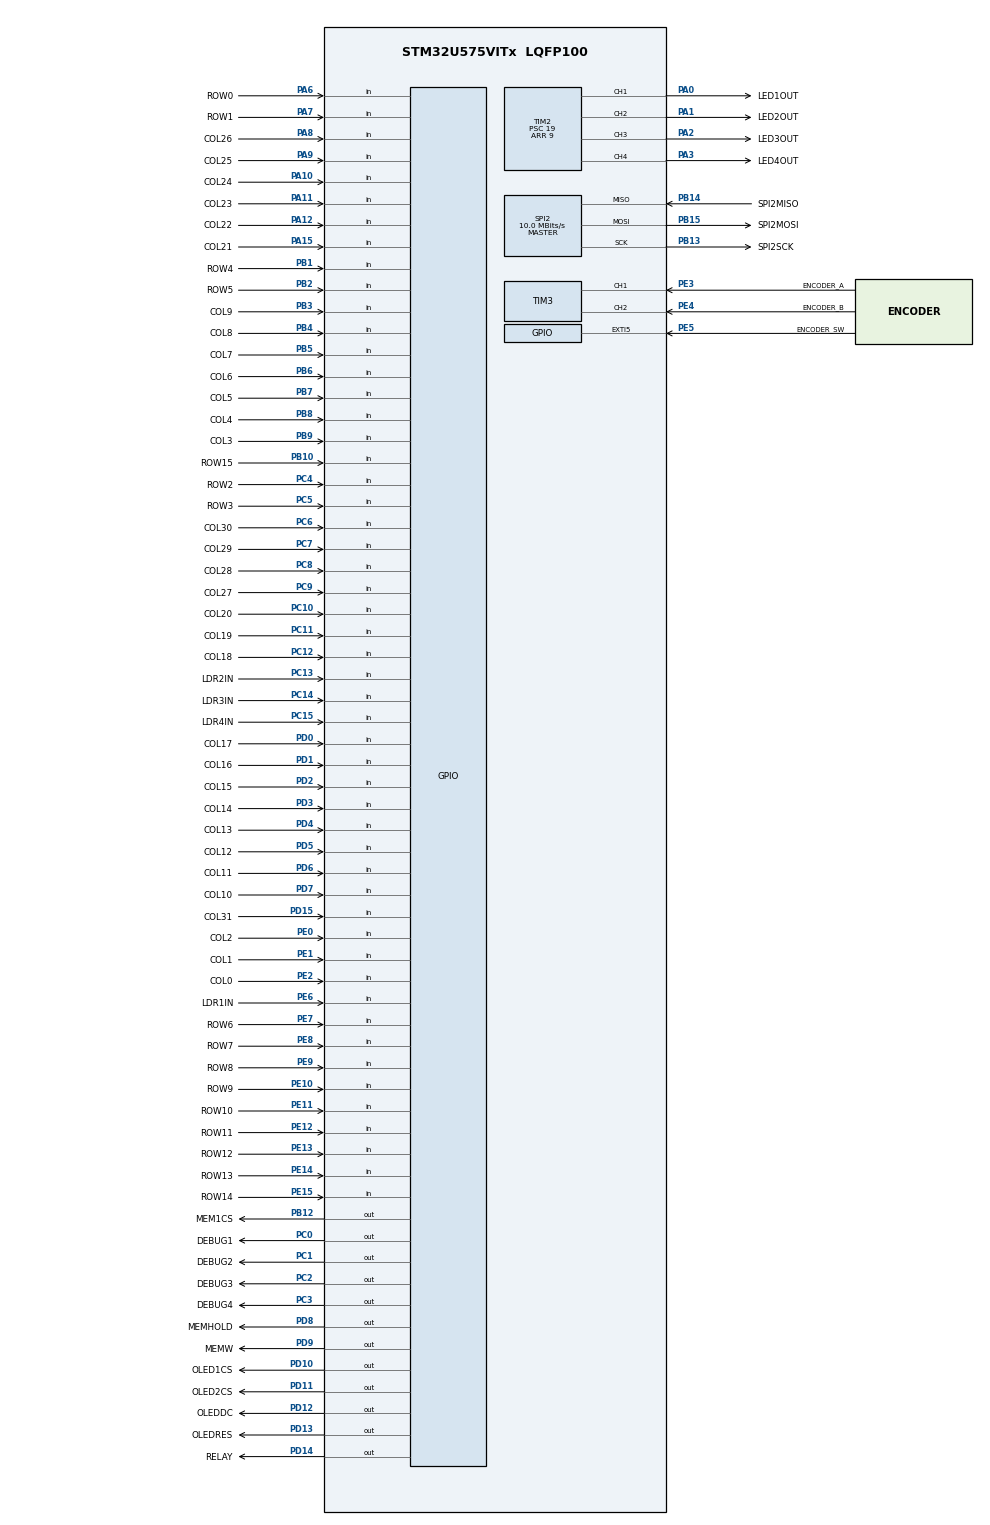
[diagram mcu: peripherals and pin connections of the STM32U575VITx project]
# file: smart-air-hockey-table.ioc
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CORTEX_M33_NS.userName=CORTEX_M33
GPDMA1.DATAHANDLING_GPDMACH0=ENABLE
GPDMA1.DATAHANDLING_GPDMACH1=ENABLE
GPDMA1.DATAHANDLING_GPDMACH2=ENABLE
GPDMA1.DATAHANDLING_GPDMACH3=ENABLE
GPDMA1.DESTDATAWIDTH_GPDMACH0=DMA_DEST_DATAWIDTH_WORD
GPDMA1.DESTDATAWIDTH_GPDMACH1=DMA_DEST_DATAWIDTH_WORD
GPDMA1.DESTDATAWIDTH_GPDMACH2=DMA_DEST_DATAWIDTH_WORD
GPDMA1.DESTDATAWIDTH_GPDMACH3=DMA_DEST_DATAWIDTH_WORD
GPDMA1.DIRECTION_GPDMACH0=DMA_MEMORY_TO_PERIPH
GPDMA1.DIRECTION_GPDMACH1=DMA_MEMORY_TO_PERIPH
GPDMA1.DIRECTION_GPDMACH2=DMA_MEMORY_TO_PERIPH
GPDMA1.DIRECTION_GPDMACH3=DMA_MEMORY_TO_PERIPH
GPDMA1.IPHANDLE_GPDMACH0-SIMPLEREQUEST_GPDMACH0=__NULL
GPDMA1.IPHANDLE_GPDMACH1-SIMPLEREQUEST_GPDMACH1=__NULL
GPDMA1.IPHANDLE_GPDMACH2-SIMPLEREQUEST_GPDMACH2=__NULL
GPDMA1.IPHANDLE_GPDMACH3-SIMPLEREQUEST_GPDMACH3=__NULL
GPDMA1.REQUEST_GPDMACH0=GPDMA1_REQUEST_TIM2_UP
GPDMA1.REQUEST_GPDMACH1=GPDMA1_REQUEST_TIM2_UP
GPDMA1.REQUEST_GPDMACH2=GPDMA1_REQUEST_TIM2_UP
GPDMA1.REQUEST_GPDMACH3=GPDMA1_REQUEST_TIM2_UP
GPDMA1.SRCINC_GPDMACH0=DMA_SINC_INCREMENTED
GPDMA1.SRCINC_GPDMACH1=DMA_SINC_INCREMENTED
GPDMA1.SRCINC_GPDMACH2=DMA_SINC_INCREMENTED
GPDMA1.SRCINC_GPDMACH3=DMA_SINC_INCREMENTED
GPDMA1.TRANSFERALLOCATEDPORTSRC_GPDMACH0=DMA_SRC_ALLOCATED_PORT1
GPDMA1.TRANSFERALLOCATEDPORTSRC_GPDMACH1=DMA_SRC_ALLOCATED_PORT1
GPDMA1.TRANSFERALLOCATEDPORTSRC_GPDMACH2=DMA_SRC_ALLOCATED_PORT1
GPDMA1.TRANSFERALLOCATEDPORTSRC_GPDMACH3=DMA_SRC_ALLOCATED_PORT1
Mcu.Family=STM32U5
Mcu.Name=STM32U575VITx
Mcu.Package=LQFP100
NVIC.EXTI5_IRQn=true\:3\:0\:true\:false\:true\:true\:true\:true
NVIC.GPDMA1_Channel0_IRQn=true\:3\:0\:true\:false\:true\:false\:true\:true
NVIC.GPDMA1_Channel1_IRQn=true\:3\:0\:true\:false\:true\:false\:true\:true
NVIC.GPDMA1_Channel2_IRQn=true\:3\:0\:true\:false\:true\:false\:true\:true
NVIC.GPDMA1_Channel3_IRQn=true\:3\:0\:true\:false\:true\:false\:true\:true
NVIC.PriorityGroup=NVIC_PRIORITYGROUP_4
NVIC.TIM6_IRQn=true\:1\:0\:true\:false\:true\:true\:true\:true
NVIC.TIM7_IRQn=true\:2\:0\:true\:false\:true\:true\:true\:true
PA0.GPIO_Label=LED1OUT
PA0.Signal=S_TIM2_CH1
PA1.GPIO_Label=LED2OUT
PA1.Signal=S_TIM2_CH2
PA10.GPIO_Label=COL24
PA10.Signal=GPIO_Input
PA11.GPIO_Label=COL23
PA11.Signal=GPIO_Input
PA12.GPIO_Label=COL22
PA12.Signal=GPIO_Input
PA13\ (JTMS/SWDIO).GPIO_Label=SWDIO
PA13\ (JTMS/SWDIO).Mode=Serial_Wire
PA13\ (JTMS/SWDIO).Signal=DEBUG_JTMS-SWDIO
PA14\ (JTCK/SWCLK).GPIO_Label=SWCLK
PA14\ (JTCK/SWCLK).Mode=Serial_Wire
PA14\ (JTCK/SWCLK).Signal=DEBUG_JTCK-SWCLK
PA15\ (JTDI).GPIO_Label=COL21
PA15\ (JTDI).Signal=GPIO_Input
PA2.GPIO_Label=LED3OUT
PA2.Signal=S_TIM2_CH3
PA3.GPIO_Label=LED4OUT
PA3.Signal=S_TIM2_CH4
PA6.GPIO_Label=ROW0
PA6.Signal=GPIO_Input
PA7.GPIO_Label=ROW1
PA7.Signal=GPIO_Input
PA8.GPIO_Label=COL26
PA8.Signal=GPIO_Input
PA9.GPIO_Label=COL25
PA9.Signal=GPIO_Input
PB1.GPIO_Label=ROW4
PB1.Signal=GPIO_Input
PB10.GPIO_Label=ROW15
PB10.Signal=GPIO_Input
PB12.GPIO_Label=MEM1CS
PB12.Signal=GPIO_Output
PB13.GPIO_Label=SPI2SCK
PB13.Mode=Full_Duplex_Master
PB13.Signal=SPI2_SCK
PB14.GPIO_Label=SPI2MISO
PB14.Mode=Full_Duplex_Master
PB14.Signal=SPI2_MISO
PB15.GPIO_Label=SPI2MOSI
PB15.Mode=Full_Duplex_Master
PB15.Signal=SPI2_MOSI
PB2.GPIO_Label=ROW5
PB2.Signal=GPIO_Input
PB3\ (JTDO/TRACESWO).GPIO_Label=COL9
PB3\ (JTDO/TRACESWO).Signal=GPIO_Input
PB4\ (NJTRST).GPIO_Label=COL8
PB4\ (NJTRST).Signal=GPIO_Input
PB5.GPIO_Label=COL7
PB5.Signal=GPIO_Input
PB6.GPIO_Label=COL6
PB6.Signal=GPIO_Input
PB7.GPIO_Label=COL5
PB7.Signal=GPIO_Input
PB8.GPIO_Label=COL4
PB8.Signal=GPIO_Input
PB9.GPIO_Label=COL3
PB9.Signal=GPIO_Input
PC0.GPIO_Label=DEBUG1
PC0.Signal=GPIO_Output
PC1.GPIO_Label=DEBUG2
PC1.Signal=GPIO_Output
PC10.GPIO_Label=COL20
PC10.Signal=GPIO_Input
PC11.GPIO_Label=COL19
PC11.Signal=GPIO_Input
PC12.GPIO_Label=COL18
PC12.Signal=GPIO_Input
PC13.GPIO_Label=LDR2IN
PC13.GPIO_PuPd=GPIO_PULLUP
PC13.Signal=GPIO_Input
PC14-OSC32_IN\ (PC14).GPIO_Label=LDR3IN
PC14-OSC32_IN\ (PC14).GPIO_PuPd=GPIO_PULLUP
PC14-OSC32_IN\ (PC14).Signal=GPIO_Input
PC15-OSC32_OUT\ (PC15).GPIO_Label=LDR4IN
PC15-OSC32_OUT\ (PC15).GPIO_PuPd=GPIO_PULLUP
PC15-OSC32_OUT\ (PC15).Signal=GPIO_Input
PC2.GPIO_Label=DEBUG3
PC2.Signal=GPIO_Output
PC3.GPIO_Label=DEBUG4
PC3.Signal=GPIO_Output
PC4.GPIO_Label=ROW2
PC4.Signal=GPIO_Input
PC5.GPIO_Label=ROW3
PC5.Signal=GPIO_Input
PC6.GPIO_Label=COL30
PC6.Signal=GPIO_Input
PC7.GPIO_Label=COL29
PC7.Signal=GPIO_Input
PC8.GPIO_Label=COL28
PC8.Signal=GPIO_Input
PC9.GPIO_Label=COL27
PC9.Signal=GPIO_Input
PD0.GPIO_Label=COL17
PD0.Signal=GPIO_Input
PD1.GPIO_Label=COL16
PD1.Signal=GPIO_Input
PD10.GPIO_Label=OLED1CS
PD10.Signal=GPIO_Output
PD11.GPIO_Label=OLED2CS
PD11.Signal=GPIO_Output
PD12.GPIO_Label=OLEDDC
PD12.Signal=GPIO_Output
PD13.GPIO_Label=OLEDRES
PD13.Signal=GPIO_Output
PD14.GPIO_Label=RELAY
PD14.Signal=GPIO_Output
PD15.GPIO_Label=COL31
PD15.Signal=GPIO_Input
PD2.GPIO_Label=COL15
PD2.Signal=GPIO_Input
PD3.GPIO_Label=COL14
PD3.Signal=GPIO_Input
PD4.GPIO_Label=COL13
PD4.Signal=GPIO_Input
PD5.GPIO_Label=COL12
PD5.Signal=GPIO_Input
PD6.GPIO_Label=COL11
PD6.Signal=GPIO_Input
PD7.GPIO_Label=COL10
PD7.Signal=GPIO_Input
PD8.GPIO_Label=MEMHOLD
PD8.Signal=GPIO_Output
PD9.GPIO_Label=MEMW
PD9.Signal=GPIO_Output
PE0.GPIO_Label=COL2
PE0.Signal=GPIO_Input
PE1.GPIO_Label=COL1
PE1.Signal=GPIO_Input
PE10.GPIO_Label=ROW9
PE10.Signal=GPIO_Input
PE11.GPIO_Label=ROW10
PE11.Signal=GPIO_Input
PE12.GPIO_Label=ROW11
PE12.Signal=GPIO_Input
PE13.GPIO_Label=ROW12
PE13.Signal=GPIO_Input
PE14.GPIO_Label=ROW13
PE14.Signal=GPIO_Input
PE15.GPIO_Label=ROW14
PE15.Signal=GPIO_Input
PE2.GPIO_Label=COL0
PE2.Signal=GPIO_Input
PE3.GPIO_Label=ENCODER_A
PE3.GPIO_PuPd=GPIO_PULLUP
PE3.Signal=S_TIM3_CH1
PE4.GPIO_Label=ENCODER_B
PE4.GPIO_PuPd=GPIO_PULLUP
PE4.Signal=S_TIM3_CH2
PE5.GPIO_Label=ENCODER_SW
PE5.GPIO_ModeDefaultEXTI=GPIO_MODE_IT_FALLING
PE5.GPIO_PuPd=GPIO_PULLUP
PE5.Signal=GPXTI5
PE6.GPIO_Label=LDR1IN
PE6.GPIO_PuPd=GPIO_PULLUP
PE6.Signal=GPIO_Input
PE7.GPIO_Label=ROW6
PE7.Signal=GPIO_Input
PE8.GPIO_Label=ROW7
PE8.Signal=GPIO_Input
PE9.GPIO_Label=ROW8
PE9.Signal=GPIO_Input
PH0-OSC_IN\ (PH0).GPIO_Label=OSC_IN
PH0-OSC_IN\ (PH0).Mode=HSE-External-Clock-Source
PH0-OSC_IN\ (PH0).Signal=RCC_OSC_IN
ProjectManager.HeapSize=0x200
ProjectManager.StackSize=0x400
ProjectManager.TargetToolchain=STM32CubeIDE
RCC.ADCFreq_Value=16000000
RCC.AHBFreq_Value=160000000
RCC.APB1Freq_Value=160000000
RCC.APB1TimFreq_Value=160000000
RCC.APB2Freq_Value=160000000
RCC.APB2TimFreq_Value=160000000
RCC.APB3Freq_Value=160000000
RCC.CortexFreq_Value=160000000
RCC.EPOD_VALUE=4000000
RCC.HCLKFreq_Value=160000000
RCC.HSE_VALUE=16000000
RCC.HSI48_VALUE=48000000
RCC.HSI_VALUE=16000000
RCC.LSE_VALUE=32768
RCC.LSIDIV_VALUE=32000
RCC.MSI_VALUE=4000000
RCC.PLLN=80
RCC.SYSCLKFreq_VALUE=160000000
RCC.SYSCLKSource=RCC_SYSCLKSOURCE_PLLCLK
RCC.USBFreq_Value=48000000
RCC.VCOOutputFreq_Value=320000000
SH.S_TIM2_CH1.0=TIM2_CH1,PWM Generation1 CH1
SH.S_TIM2_CH2.0=TIM2_CH2,PWM Generation2 CH2
SH.S_TIM2_CH3.0=TIM2_CH3,PWM Generation3 CH3
SH.S_TIM2_CH4.0=TIM2_CH4,PWM Generation4 CH4
SH.S_TIM3_CH1.0=TIM3_CH1,Encoder_Interface
SH.S_TIM3_CH2.0=TIM3_CH2,Encoder_Interface
SPI2.BaudRatePrescaler=SPI_BAUDRATEPRESCALER_16
SPI2.CalculateBaudRate=10.0 MBits/s
SPI2.DataSize=SPI_DATASIZE_8BIT
SPI2.Direction=SPI_DIRECTION_2LINES
SPI2.Mode=SPI_MODE_MASTER
SPI2.VirtualType=VM_MASTER
TIM2.Channel-PWM\ Generation1\ CH1=TIM_CHANNEL_1
TIM2.Channel-PWM\ Generation2\ CH2=TIM_CHANNEL_2
TIM2.Channel-PWM\ Generation3\ CH3=TIM_CHANNEL_3
TIM2.Channel-PWM\ Generation4\ CH4=TIM_CHANNEL_4
TIM2.PeriodNoDither=9
TIM2.Prescaler=19
TIM3.EncoderMode=TIM_ENCODERMODE_TI12
TIM3.IC1Filter=8
TIM3.IC2Filter=8
TIM6.PeriodNoDither=9
TIM6.Prescaler=15999
TIM7.PeriodNoDither=9
TIM7.Prescaler=15999
VP_GPDMA1_VS_GPDMACH0.Mode=SIMPLEREQUEST_GPDMACH0
VP_GPDMA1_VS_GPDMACH1.Mode=SIMPLEREQUEST_GPDMACH1
VP_GPDMA1_VS_GPDMACH2.Mode=SIMPLEREQUEST_GPDMACH2
VP_GPDMA1_VS_GPDMACH3.Mode=SIMPLEREQUEST_GPDMACH3
VP_ICACHE_VS_ICACHE.Mode=DirectMappedCache
VP_LPBAMQUEUE_VS_QUEUE.Mode=QUEUEMODE
VP_LPBAM_VS_SIG1.Mode=SmartRun
VP_LPBAM_VS_SIG4.Mode=LPDMA1
VP_MEMORYMAP_VS_MEMORYMAP.Mode=CurAppReg
VP_PWR_VS_SECSignals.Mode=Security/Privilege
VP_TIM2_VS_ClockSourceINT.Mode=Internal
VP_TIM6_VS_ClockSourceINT.Mode=Enable_Timer
VP_TIM7_VS_ClockSourceINT.Mode=Enable_Timer
board=custom

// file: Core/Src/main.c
/* USER CODE BEGIN Header */
/**
  ******************************************************************************
  * @file           : main.c
  * @brief          : Main program body
  ******************************************************************************
  * @attention
  *
  * Copyright (c) 2023 STMicroelectronics.
  * All rights reserved.
  *
  * This software is licensed under terms that can be found in the LICENSE file
  * in the root directory of this software component.
  * If no LICENSE file comes with this software, it is provided AS-IS.
  *
  ******************************************************************************
  */
/* USER CODE END Header */
#include "main.h"

/* USER CODE BEGIN Includes */
#include "app_core.h"
/* USER CODE END Includes */

void SystemClock_Config(void);
static void MX_GPDMA1_Init(void);
static void MX_GPIO_Init(void);
static void MX_MEMORYMAP_Init(void);
static void MX_ICACHE_Init(void);
static void MX_SPI2_Init(void);
static void MX_TIM2_Init(void);
static void MX_TIM3_Init(void);
static void MX_TIM6_Init(void);
static void MX_TIM7_Init(void);

int main(void)
{

  /* MCU Configuration--------------------------------------------------------*/

  /* Reset of all peripherals, Initializes the Flash interface and the Systick. */
  HAL_Init();

  /* Enable PWR clock interface */

  LL_AHB3_GRP1_EnableClock(LL_AHB3_GRP1_PERIPH_PWR);

  /* Configure the system clock */
  SystemClock_Config();

  /* Initialize all configured peripherals */
  MX_GPDMA1_Init();
  MX_GPIO_Init();
  MX_MEMORYMAP_Init();
  MX_ICACHE_Init();
  MX_SPI2_Init();
  MX_TIM2_Init();
  MX_TIM3_Init();
  MX_TIM6_Init();
  MX_TIM7_Init();
  /* USER CODE BEGIN 2 */
  App_Init();
  /* USER CODE END 2 */

  /* Infinite loop */
  while (1)
  {

    /* USER CODE BEGIN 3 */
    asm("wfi");
  }
  /* USER CODE END 3 */
}

void SystemClock_Config(void)
{
  LL_FLASH_SetLatency(LL_FLASH_LATENCY_4);
  while(LL_FLASH_GetLatency()!= LL_FLASH_LATENCY_4)
  {
  }

  LL_PWR_SetRegulVoltageScaling(LL_PWR_REGU_VOLTAGE_SCALE1);
  while (LL_PWR_IsActiveFlag_VOS() == 0)
  {
  }
  LL_RCC_MSIS_Enable();

   /* Wait till MSIS is ready */
  while(LL_RCC_MSIS_IsReady() != 1)
  {
  }

  LL_RCC_MSI_EnableRangeSelection();
  LL_RCC_MSIS_SetRange(LL_RCC_MSISRANGE_4);
  LL_RCC_MSI_SetCalibTrimming(16, LL_RCC_MSI_OSCILLATOR_1);
  LL_RCC_PLL1_ConfigDomain_SYS(LL_RCC_PLL1SOURCE_MSIS, 1, 80, 2);
  LL_RCC_PLL1_EnableDomain_SYS();
  LL_RCC_SetPll1EPodPrescaler(LL_RCC_PLL1MBOOST_DIV_1);
  LL_RCC_PLL1_SetVCOInputRange(LL_RCC_PLLINPUTRANGE_4_8);
  LL_RCC_PLL1_Enable();

   /* Wait till PLL is ready */
  while(LL_RCC_PLL1_IsReady() != 1)
  {
  }

   /* Intermediate AHB prescaler 2 when target frequency clock is higher than 80 MHz */
  LL_RCC_SetAHBPrescaler(LL_RCC_SYSCLK_DIV_2);

  LL_RCC_SetSysClkSource(LL_RCC_SYS_CLKSOURCE_PLL1);

   /* Wait till System clock is ready */
  while(LL_RCC_GetSysClkSource() != LL_RCC_SYS_CLKSOURCE_STATUS_PLL1)
  {
  }

  /* Insure 1us transition state at intermediate medium speed clock*/
  for (__IO uint32_t i = (160 >> 1); i !=0; i--);

  LL_RCC_SetAHBPrescaler(LL_RCC_SYSCLK_DIV_1);
  LL_RCC_SetAPB1Prescaler(LL_RCC_APB1_DIV_1);
  LL_RCC_SetAPB2Prescaler(LL_RCC_APB2_DIV_1);
  LL_RCC_SetAPB3Prescaler(LL_RCC_APB3_DIV_1);
  LL_SetSystemCoreClock(160000000);

   /* Update the time base */
  if (HAL_InitTick (TICK_INT_PRIORITY) != HAL_OK)
  {
    Error_Handler();
  }
}

static void MX_GPDMA1_Init(void)
{

  /* Peripheral clock enable */
  LL_AHB1_GRP1_EnableClock(LL_AHB1_GRP1_PERIPH_GPDMA1);

  /* GPDMA1 interrupt Init */
  NVIC_SetPriority(GPDMA1_Channel0_IRQn, NVIC_EncodePriority(NVIC_GetPriorityGrouping(),3, 0));
  NVIC_EnableIRQ(GPDMA1_Channel0_IRQn);
  NVIC_SetPriority(GPDMA1_Channel1_IRQn, NVIC_EncodePriority(NVIC_GetPriorityGrouping(),3, 0));
  NVIC_EnableIRQ(GPDMA1_Channel1_IRQn);
  NVIC_SetPriority(GPDMA1_Channel2_IRQn, NVIC_EncodePriority(NVIC_GetPriorityGrouping(),3, 0));
  NVIC_EnableIRQ(GPDMA1_Channel2_IRQn);
  NVIC_SetPriority(GPDMA1_Channel3_IRQn, NVIC_EncodePriority(NVIC_GetPriorityGrouping(),3, 0));
  NVIC_EnableIRQ(GPDMA1_Channel3_IRQn);

}

static void MX_ICACHE_Init(void)
{

  /** Enable instruction cache in 1-way (direct mapped cache)
  */
  LL_ICACHE_SetMode(LL_ICACHE_1WAY);
  LL_ICACHE_Enable();

}

static void MX_MEMORYMAP_Init(void)
{

}

static void MX_SPI2_Init(void)
{

  LL_SPI_InitTypeDef SPI_InitStruct = {0};

  LL_GPIO_InitTypeDef GPIO_InitStruct = {0};

  LL_RCC_SetSPIClockSource(LL_RCC_SPI2_CLKSOURCE_SYSCLK);

  /* Peripheral clock enable */
  LL_APB1_GRP1_EnableClock(LL_APB1_GRP1_PERIPH_SPI2);

  LL_AHB2_GRP1_EnableClock(LL_AHB2_GRP1_PERIPH_GPIOB);
  /**SPI2 GPIO Configuration
  PB13   ------> SPI2_SCK
  PB14   ------> SPI2_MISO
  PB15   ------> SPI2_MOSI
  */
  GPIO_InitStruct.Pin = SPI2SCK_Pin|SPI2MISO_Pin|SPI2MOSI_Pin;
  GPIO_InitStruct.Mode = LL_GPIO_MODE_ALTERNATE;
  GPIO_InitStruct.Speed = LL_GPIO_SPEED_FREQ_LOW;
  GPIO_InitStruct.OutputType = LL_GPIO_OUTPUT_PUSHPULL;
  GPIO_InitStruct.Pull = LL_GPIO_PULL_NO;
  GPIO_InitStruct.Alternate = LL_GPIO_AF_5;
  LL_GPIO_Init(GPIOB, &GPIO_InitStruct);

  /* SPI2 parameter configuration*/
  SPI_InitStruct.TransferDirection = LL_SPI_FULL_DUPLEX;
  SPI_InitStruct.Mode = LL_SPI_MODE_MASTER;
  SPI_InitStruct.DataWidth = LL_SPI_DATAWIDTH_8BIT;
  SPI_InitStruct.ClockPolarity = LL_SPI_POLARITY_LOW;
  SPI_InitStruct.ClockPhase = LL_SPI_PHASE_1EDGE;
  SPI_InitStruct.NSS = LL_SPI_NSS_SOFT;
  SPI_InitStruct.BaudRate = LL_SPI_BAUDRATEPRESCALER_DIV16;
  SPI_InitStruct.BitOrder = LL_SPI_MSB_FIRST;
  SPI_InitStruct.CRCCalculation = LL_SPI_CRCCALCULATION_DISABLE;
  SPI_InitStruct.CRCPoly = 0x7;
  LL_SPI_Init(SPI2, &SPI_InitStruct);
  LL_SPI_SetStandard(SPI2, LL_SPI_PROTOCOL_MOTOROLA);
  LL_SPI_EnableNSSPulseMgt(SPI2);

}

static void MX_TIM2_Init(void)
{

  LL_TIM_InitTypeDef TIM_InitStruct = {0};
  LL_TIM_OC_InitTypeDef TIM_OC_InitStruct = {0};

  LL_DMA_InitTypeDef DMA_InitStruct = {0};
  LL_GPIO_InitTypeDef GPIO_InitStruct = {0};

  /* Peripheral clock enable */
  LL_APB1_GRP1_EnableClock(LL_APB1_GRP1_PERIPH_TIM2);

  /* TIM2 DMA Init */

  /* GPDMA1_REQUEST_TIM2_UP Init */
  DMA_InitStruct.SrcAddress = 0x00000000U;
  DMA_InitStruct.DestAddress = 0x00000000U;
  DMA_InitStruct.Direction = LL_DMA_DIRECTION_MEMORY_TO_PERIPH;
  DMA_InitStruct.BlkHWRequest = LL_DMA_HWREQUEST_SINGLEBURST;
  DMA_InitStruct.DataAlignment = LL_DMA_DATA_ALIGN_ZEROPADD;
  DMA_InitStruct.SrcBurstLength = 1;
  DMA_InitStruct.DestBurstLength = 1;
  DMA_InitStruct.SrcDataWidth = LL_DMA_SRC_DATAWIDTH_BYTE;
  DMA_InitStruct.DestDataWidth = LL_DMA_DEST_DATAWIDTH_WORD;
  DMA_InitStruct.SrcIncMode = LL_DMA_SRC_INCREMENT;
  DMA_InitStruct.DestIncMode = LL_DMA_DEST_FIXED;
  DMA_InitStruct.Priority = LL_DMA_LOW_PRIORITY_LOW_WEIGHT;
  DMA_InitStruct.BlkDataLength = 0x00000000U;
  DMA_InitStruct.TriggerMode = LL_DMA_TRIGM_BLK_TRANSFER;
  DMA_InitStruct.TriggerPolarity = LL_DMA_TRIG_POLARITY_MASKED;
  DMA_InitStruct.TriggerSelection = 0x00000000U;
  DMA_InitStruct.Request = LL_GPDMA1_REQUEST_TIM2_UP;
  DMA_InitStruct.TransferEventMode = LL_DMA_TCEM_BLK_TRANSFER;
  DMA_InitStruct.SrcAllocatedPort = LL_DMA_SRC_ALLOCATED_PORT1;
  DMA_InitStruct.DestAllocatedPort = LL_DMA_DEST_ALLOCATED_PORT0;
  DMA_InitStruct.LinkAllocatedPort = LL_DMA_LINK_ALLOCATED_PORT1;
  DMA_InitStruct.LinkStepMode = LL_DMA_LSM_FULL_EXECUTION;
  DMA_InitStruct.LinkedListBaseAddr = 0x00000000U;
  DMA_InitStruct.LinkedListAddrOffset = 0x00000000U;
  LL_DMA_Init(GPDMA1, LL_DMA_CHANNEL_3, &DMA_InitStruct);

  /* GPDMA1_REQUEST_TIM2_UP Init */
  DMA_InitStruct.SrcAddress = 0x00000000U;
  DMA_InitStruct.DestAddress = 0x00000000U;
  DMA_InitStruct.Direction = LL_DMA_DIRECTION_MEMORY_TO_PERIPH;
  DMA_InitStruct.BlkHWRequest = LL_DMA_HWREQUEST_SINGLEBURST;
  DMA_InitStruct.DataAlignment = LL_DMA_DATA_ALIGN_ZEROPADD;
  DMA_InitStruct.SrcBurstLength = 1;
  DMA_InitStruct.DestBurstLength = 1;
  DMA_InitStruct.SrcDataWidth = LL_DMA_SRC_DATAWIDTH_BYTE;
  DMA_InitStruct.DestDataWidth = LL_DMA_DEST_DATAWIDTH_WORD;
  DMA_InitStruct.SrcIncMode = LL_DMA_SRC_INCREMENT;
  DMA_InitStruct.DestIncMode = LL_DMA_DEST_FIXED;
  DMA_InitStruct.Priority = LL_DMA_LOW_PRIORITY_LOW_WEIGHT;
  DMA_InitStruct.BlkDataLength = 0x00000000U;
  DMA_InitStruct.TriggerMode = LL_DMA_TRIGM_BLK_TRANSFER;
  DMA_InitStruct.TriggerPolarity = LL_DMA_TRIG_POLARITY_MASKED;
  DMA_InitStruct.TriggerSelection = 0x00000000U;
  DMA_InitStruct.Request = LL_GPDMA1_REQUEST_TIM2_UP;
  DMA_InitStruct.TransferEventMode = LL_DMA_TCEM_BLK_TRANSFER;
  DMA_InitStruct.SrcAllocatedPort = LL_DMA_SRC_ALLOCATED_PORT1;
  DMA_InitStruct.DestAllocatedPort = LL_DMA_DEST_ALLOCATED_PORT0;
  DMA_InitStruct.LinkAllocatedPort = LL_DMA_LINK_ALLOCATED_PORT1;
  DMA_InitStruct.LinkStepMode = LL_DMA_LSM_FULL_EXECUTION;
  DMA_InitStruct.LinkedListBaseAddr = 0x00000000U;
  DMA_InitStruct.LinkedListAddrOffset = 0x00000000U;
  LL_DMA_Init(GPDMA1, LL_DMA_CHANNEL_2, &DMA_InitStruct);

  /* GPDMA1_REQUEST_TIM2_UP Init */
  DMA_InitStruct.SrcAddress = 0x00000000U;
  DMA_InitStruct.DestAddress = 0x00000000U;
  DMA_InitStruct.Direction = LL_DMA_DIRECTION_MEMORY_TO_PERIPH;
  DMA_InitStruct.BlkHWRequest = LL_DMA_HWREQUEST_SINGLEBURST;
  DMA_InitStruct.DataAlignment = LL_DMA_DATA_ALIGN_ZEROPADD;
  DMA_InitStruct.SrcBurstLength = 1;
  DMA_InitStruct.DestBurstLength = 1;
  DMA_InitStruct.SrcDataWidth = LL_DMA_SRC_DATAWIDTH_BYTE;
  DMA_InitStruct.DestDataWidth = LL_DMA_DEST_DATAWIDTH_WORD;
  DMA_InitStruct.SrcIncMode = LL_DMA_SRC_INCREMENT;
  DMA_InitStruct.DestIncMode = LL_DMA_DEST_FIXED;
  DMA_InitStruct.Priority = LL_DMA_LOW_PRIORITY_LOW_WEIGHT;
  DMA_InitStruct.BlkDataLength = 0x00000000U;
  DMA_InitStruct.TriggerMode = LL_DMA_TRIGM_BLK_TRANSFER;
  DMA_InitStruct.TriggerPolarity = LL_DMA_TRIG_POLARITY_MASKED;
  DMA_InitStruct.TriggerSelection = 0x00000000U;
  DMA_InitStruct.Request = LL_GPDMA1_REQUEST_TIM2_UP;
  DMA_InitStruct.TransferEventMode = LL_DMA_TCEM_BLK_TRANSFER;
  DMA_InitStruct.SrcAllocatedPort = LL_DMA_SRC_ALLOCATED_PORT1;
  DMA_InitStruct.DestAllocatedPort = LL_DMA_DEST_ALLOCATED_PORT0;
  DMA_InitStruct.LinkAllocatedPort = LL_DMA_LINK_ALLOCATED_PORT1;
  DMA_InitStruct.LinkStepMode = LL_DMA_LSM_FULL_EXECUTION;
  DMA_InitStruct.LinkedListBaseAddr = 0x00000000U;
  DMA_InitStruct.LinkedListAddrOffset = 0x00000000U;
  LL_DMA_Init(GPDMA1, LL_DMA_CHANNEL_1, &DMA_InitStruct);

  /* GPDMA1_REQUEST_TIM2_UP Init */
  DMA_InitStruct.SrcAddress = 0x00000000U;
  DMA_InitStruct.DestAddress = 0x00000000U;
  DMA_InitStruct.Direction = LL_DMA_DIRECTION_MEMORY_TO_PERIPH;
  DMA_InitStruct.BlkHWRequest = LL_DMA_HWREQUEST_SINGLEBURST;
  DMA_InitStruct.DataAlignment = LL_DMA_DATA_ALIGN_ZEROPADD;
  DMA_InitStruct.SrcBurstLength = 1;
  DMA_InitStruct.DestBurstLength = 1;
  DMA_InitStruct.SrcDataWidth = LL_DMA_SRC_DATAWIDTH_BYTE;
  DMA_InitStruct.DestDataWidth = LL_DMA_DEST_DATAWIDTH_WORD;
  DMA_InitStruct.SrcIncMode = LL_DMA_SRC_INCREMENT;
  DMA_InitStruct.DestIncMode = LL_DMA_DEST_FIXED;
  DMA_InitStruct.Priority = LL_DMA_LOW_PRIORITY_LOW_WEIGHT;
  DMA_InitStruct.BlkDataLength = 0x00000000U;
  DMA_InitStruct.TriggerMode = LL_DMA_TRIGM_BLK_TRANSFER;
  DMA_InitStruct.TriggerPolarity = LL_DMA_TRIG_POLARITY_MASKED;
  DMA_InitStruct.TriggerSelection = 0x00000000U;
  DMA_InitStruct.Request = LL_GPDMA1_REQUEST_TIM2_UP;
  DMA_InitStruct.TransferEventMode = LL_DMA_TCEM_BLK_TRANSFER;
  DMA_InitStruct.SrcAllocatedPort = LL_DMA_SRC_ALLOCATED_PORT1;
  DMA_InitStruct.DestAllocatedPort = LL_DMA_DEST_ALLOCATED_PORT0;
  DMA_InitStruct.LinkAllocatedPort = LL_DMA_LINK_ALLOCATED_PORT1;
  DMA_InitStruct.LinkStepMode = LL_DMA_LSM_FULL_EXECUTION;
  DMA_InitStruct.LinkedListBaseAddr = 0x00000000U;
  DMA_InitStruct.LinkedListAddrOffset = 0x00000000U;
  LL_DMA_Init(GPDMA1, LL_DMA_CHANNEL_0, &DMA_InitStruct);

  TIM_InitStruct.Prescaler = 19;
  TIM_InitStruct.CounterMode = LL_TIM_COUNTERMODE_UP;
  TIM_InitStruct.Autoreload = 9;
  TIM_InitStruct.ClockDivision = LL_TIM_CLOCKDIVISION_DIV1;
  LL_TIM_Init(TIM2, &TIM_InitStruct);
  LL_TIM_DisableARRPreload(TIM2);
  LL_TIM_SetClockSource(TIM2, LL_TIM_CLOCKSOURCE_INTERNAL);
  LL_TIM_OC_EnablePreload(TIM2, LL_TIM_CHANNEL_CH1);
  TIM_OC_InitStruct.OCMode = LL_TIM_OCMODE_PWM1;
  TIM_OC_InitStruct.OCState = LL_TIM_OCSTATE_DISABLE;
  TIM_OC_InitStruct.OCNState = LL_TIM_OCSTATE_DISABLE;
  TIM_OC_InitStruct.CompareValue = 0;
  TIM_OC_InitStruct.OCPolarity = LL_TIM_OCPOLARITY_HIGH;
  LL_TIM_OC_Init(TIM2, LL_TIM_CHANNEL_CH1, &TIM_OC_InitStruct);
  LL_TIM_OC_DisableFast(TIM2, LL_TIM_CHANNEL_CH1);
  LL_TIM_OC_EnablePreload(TIM2, LL_TIM_CHANNEL_CH2);
  LL_TIM_OC_Init(TIM2, LL_TIM_CHANNEL_CH2, &TIM_OC_InitStruct);
  LL_TIM_OC_DisableFast(TIM2, LL_TIM_CHANNEL_CH2);
  LL_TIM_OC_EnablePreload(TIM2, LL_TIM_CHANNEL_CH3);
  LL_TIM_OC_Init(TIM2, LL_TIM_CHANNEL_CH3, &TIM_OC_InitStruct);
  LL_TIM_OC_DisableFast(TIM2, LL_TIM_CHANNEL_CH3);
  LL_TIM_OC_EnablePreload(TIM2, LL_TIM_CHANNEL_CH4);
  LL_TIM_OC_Init(TIM2, LL_TIM_CHANNEL_CH4, &TIM_OC_InitStruct);
  LL_TIM_OC_DisableFast(TIM2, LL_TIM_CHANNEL_CH4);
  LL_TIM_SetTriggerOutput(TIM2, LL_TIM_TRGO_RESET);
  LL_TIM_DisableMasterSlaveMode(TIM2);
  LL_AHB2_GRP1_EnableClock(LL_AHB2_GRP1_PERIPH_GPIOA);
  /**TIM2 GPIO Configuration
  PA0   ------> TIM2_CH1
  PA1   ------> TIM2_CH2
  PA2   ------> TIM2_CH3
  PA3   ------> TIM2_CH4
  */
  GPIO_InitStruct.Pin = LED1OUT_Pin|LED2OUT_Pin|LED3OUT_Pin|LED4OUT_Pin;
  GPIO_InitStruct.Mode = LL_GPIO_MODE_ALTERNATE;
  GPIO_InitStruct.Speed = LL_GPIO_SPEED_FREQ_LOW;
  GPIO_InitStruct.OutputType = LL_GPIO_OUTPUT_PUSHPULL;
  GPIO_InitStruct.Pull = LL_GPIO_PULL_NO;
  GPIO_InitStruct.Alternate = LL_GPIO_AF_1;
  LL_GPIO_Init(GPIOA, &GPIO_InitStruct);

}

static void MX_TIM3_Init(void)
{

  LL_TIM_InitTypeDef TIM_InitStruct = {0};

  LL_GPIO_InitTypeDef GPIO_InitStruct = {0};

  /* Peripheral clock enable */
  LL_APB1_GRP1_EnableClock(LL_APB1_GRP1_PERIPH_TIM3);

  LL_AHB2_GRP1_EnableClock(LL_AHB2_GRP1_PERIPH_GPIOE);
  /**TIM3 GPIO Configuration
  PE3   ------> TIM3_CH1
  PE4   ------> TIM3_CH2
  */
  GPIO_InitStruct.Pin = ENCODER_A_Pin|ENCODER_B_Pin;
  GPIO_InitStruct.Mode = LL_GPIO_MODE_ALTERNATE;
  GPIO_InitStruct.Speed = LL_GPIO_SPEED_FREQ_LOW;
  GPIO_InitStruct.OutputType = LL_GPIO_OUTPUT_PUSHPULL;
  GPIO_InitStruct.Pull = LL_GPIO_PULL_UP;
  GPIO_InitStruct.Alternate = LL_GPIO_AF_2;
  LL_GPIO_Init(GPIOE, &GPIO_InitStruct);

  TIM_InitStruct.Prescaler = 0;
  TIM_InitStruct.CounterMode = LL_TIM_COUNTERMODE_UP;
  TIM_InitStruct.Autoreload = 4.294967295E9;
  TIM_InitStruct.ClockDivision = LL_TIM_CLOCKDIVISION_DIV1;
  LL_TIM_Init(TIM3, &TIM_InitStruct);
  LL_TIM_DisableARRPreload(TIM3);
  LL_TIM_SetEncoderMode(TIM3, LL_TIM_ENCODERMODE_X4_TI12);
  LL_TIM_IC_SetActiveInput(TIM3, LL_TIM_CHANNEL_CH1, LL_TIM_ACTIVEINPUT_DIRECTTI);
  LL_TIM_IC_SetPrescaler(TIM3, LL_TIM_CHANNEL_CH1, LL_TIM_ICPSC_DIV1);
  LL_TIM_IC_SetFilter(TIM3, LL_TIM_CHANNEL_CH1, LL_TIM_IC_FILTER_FDIV8_N6);
  LL_TIM_IC_SetPolarity(TIM3, LL_TIM_CHANNEL_CH1, LL_TIM_IC_POLARITY_RISING);
  LL_TIM_IC_SetActiveInput(TIM3, LL_TIM_CHANNEL_CH2, LL_TIM_ACTIVEINPUT_DIRECTTI);
  LL_TIM_IC_SetPrescaler(TIM3, LL_TIM_CHANNEL_CH2, LL_TIM_ICPSC_DIV1);
  LL_TIM_IC_SetFilter(TIM3, LL_TIM_CHANNEL_CH2, LL_TIM_IC_FILTER_FDIV8_N6);
  LL_TIM_IC_SetPolarity(TIM3, LL_TIM_CHANNEL_CH2, LL_TIM_IC_POLARITY_RISING);
  LL_TIM_SetTriggerOutput(TIM3, LL_TIM_TRGO_RESET);
  LL_TIM_DisableMasterSlaveMode(TIM3);

}

static void MX_TIM6_Init(void)
{

  LL_TIM_InitTypeDef TIM_InitStruct = {0};

  /* Peripheral clock enable */
  LL_APB1_GRP1_EnableClock(LL_APB1_GRP1_PERIPH_TIM6);

  /* TIM6 interrupt Init */
  NVIC_SetPriority(TIM6_IRQn, NVIC_EncodePriority(NVIC_GetPriorityGrouping(),1, 0));
  NVIC_EnableIRQ(TIM6_IRQn);

  TIM_InitStruct.Prescaler = 63999;
  TIM_InitStruct.CounterMode = LL_TIM_COUNTERMODE_UP;
  TIM_InitStruct.Autoreload = 9;
  LL_TIM_Init(TIM6, &TIM_InitStruct);
  LL_TIM_DisableARRPreload(TIM6);
  LL_TIM_SetTriggerOutput(TIM6, LL_TIM_TRGO_RESET);
  LL_TIM_DisableMasterSlaveMode(TIM6);

}

static void MX_TIM7_Init(void)
{

  LL_TIM_InitTypeDef TIM_InitStruct = {0};

  /* Peripheral clock enable */
  LL_APB1_GRP1_EnableClock(LL_APB1_GRP1_PERIPH_TIM7);

  /* TIM7 interrupt Init */
  NVIC_SetPriority(TIM7_IRQn, NVIC_EncodePriority(NVIC_GetPriorityGrouping(),2, 0));
  NVIC_EnableIRQ(TIM7_IRQn);

  TIM_InitStruct.Prescaler = 63999;
  TIM_InitStruct.CounterMode = LL_TIM_COUNTERMODE_UP;
  TIM_InitStruct.Autoreload = 9;
  LL_TIM_Init(TIM7, &TIM_InitStruct);
  LL_TIM_DisableARRPreload(TIM7);
  LL_TIM_SetTriggerOutput(TIM7, LL_TIM_TRGO_RESET);
  LL_TIM_DisableMasterSlaveMode(TIM7);

}

static void MX_GPIO_Init(void)
{
  LL_EXTI_InitTypeDef EXTI_InitStruct = {0};
  LL_GPIO_InitTypeDef GPIO_InitStruct = {0};

  /* GPIO Ports Clock Enable */
  LL_AHB2_GRP1_EnableClock(LL_AHB2_GRP1_PERIPH_GPIOE);
  LL_AHB2_GRP1_EnableClock(LL_AHB2_GRP1_PERIPH_GPIOC);
  LL_AHB2_GRP1_EnableClock(LL_AHB2_GRP1_PERIPH_GPIOH);
  LL_AHB2_GRP1_EnableClock(LL_AHB2_GRP1_PERIPH_GPIOA);
  LL_AHB2_GRP1_EnableClock(LL_AHB2_GRP1_PERIPH_GPIOB);
  LL_AHB2_GRP1_EnableClock(LL_AHB2_GRP1_PERIPH_GPIOD);

  /**/
  LL_GPIO_ResetOutputPin(GPIOC, DEBUG1_Pin|DEBUG2_Pin|DEBUG3_Pin|DEBUG4_Pin);

  /**/
  LL_GPIO_ResetOutputPin(MEM1CS_GPIO_Port, MEM1CS_Pin);

  /**/
  LL_GPIO_ResetOutputPin(GPIOD, MEMHOLD_Pin|MEMW_Pin|OLED1CS_Pin|OLED2CS_Pin
                          |OLEDDC_Pin|OLEDRES_Pin|RELAY_Pin);

  /**/
  GPIO_InitStruct.Pin = COL0_Pin|ROW6_Pin|ROW7_Pin|ROW8_Pin
                          |ROW9_Pin|ROW10_Pin|ROW11_Pin|ROW12_Pin
                          |ROW13_Pin|ROW14_Pin|COL2_Pin|COL1_Pin;
  GPIO_InitStruct.Mode = LL_GPIO_MODE_INPUT;
  GPIO_InitStruct.Pull = LL_GPIO_PULL_NO;
  LL_GPIO_Init(GPIOE, &GPIO_InitStruct);

  /**/
  GPIO_InitStruct.Pin = LDR1IN_Pin;
  GPIO_InitStruct.Mode = LL_GPIO_MODE_INPUT;
  GPIO_InitStruct.Pull = LL_GPIO_PULL_UP;
  LL_GPIO_Init(LDR1IN_GPIO_Port, &GPIO_InitStruct);

  /**/
  GPIO_InitStruct.Pin = LDR2IN_Pin|LDR3IN_Pin|LDR4IN_Pin;
  GPIO_InitStruct.Mode = LL_GPIO_MODE_INPUT;
  GPIO_InitStruct.Pull = LL_GPIO_PULL_UP;
  LL_GPIO_Init(GPIOC, &GPIO_InitStruct);

  /**/
  GPIO_InitStruct.Pin = DEBUG1_Pin|DEBUG2_Pin|DEBUG3_Pin|DEBUG4_Pin;
  GPIO_InitStruct.Mode = LL_GPIO_MODE_OUTPUT;
  GPIO_InitStruct.Speed = LL_GPIO_SPEED_FREQ_LOW;
  GPIO_InitStruct.OutputType = LL_GPIO_OUTPUT_PUSHPULL;
  GPIO_InitStruct.Pull = LL_GPIO_PULL_NO;
  LL_GPIO_Init(GPIOC, &GPIO_InitStruct);

  /**/
  GPIO_InitStruct.Pin = ROW0_Pin|ROW1_Pin|COL26_Pin|COL25_Pin
                          |COL24_Pin|COL23_Pin|COL22_Pin|COL21_Pin;
  GPIO_InitStruct.Mode = LL_GPIO_MODE_INPUT;
  GPIO_InitStruct.Pull = LL_GPIO_PULL_NO;
  LL_GPIO_Init(GPIOA, &GPIO_InitStruct);

  /**/
  GPIO_InitStruct.Pin = ROW2_Pin|ROW3_Pin|COL30_Pin|COL29_Pin
                          |COL28_Pin|COL27_Pin|COL20_Pin|COL19_Pin
                          |COL18_Pin;
  GPIO_InitStruct.Mode = LL_GPIO_MODE_INPUT;
  GPIO_InitStruct.Pull = LL_GPIO_PULL_NO;
  LL_GPIO_Init(GPIOC, &GPIO_InitStruct);

  /**/
  GPIO_InitStruct.Pin = ROW4_Pin|ROW5_Pin|ROW15_Pin|COL9_Pin
                          |COL8_Pin|COL7_Pin|COL6_Pin|COL5_Pin
                          |COL4_Pin|COL3_Pin;
  GPIO_InitStruct.Mode = LL_GPIO_MODE_INPUT;
  GPIO_InitStruct.Pull = LL_GPIO_PULL_NO;
  LL_GPIO_Init(GPIOB, &GPIO_InitStruct);

  /**/
  GPIO_InitStruct.Pin = MEM1CS_Pin;
  GPIO_InitStruct.Mode = LL_GPIO_MODE_OUTPUT;
  GPIO_InitStruct.Speed = LL_GPIO_SPEED_FREQ_LOW;
  GPIO_InitStruct.OutputType = LL_GPIO_OUTPUT_PUSHPULL;
  GPIO_InitStruct.Pull = LL_GPIO_PULL_NO;
  LL_GPIO_Init(MEM1CS_GPIO_Port, &GPIO_InitStruct);

  /**/
  GPIO_InitStruct.Pin = MEMHOLD_Pin|MEMW_Pin|OLED1CS_Pin|OLED2CS_Pin
                          |OLEDDC_Pin|OLEDRES_Pin|RELAY_Pin;
  GPIO_InitStruct.Mode = LL_GPIO_MODE_OUTPUT;
  GPIO_InitStruct.Speed = LL_GPIO_SPEED_FREQ_LOW;
  GPIO_InitStruct.OutputType = LL_GPIO_OUTPUT_PUSHPULL;
  GPIO_InitStruct.Pull = LL_GPIO_PULL_NO;
  LL_GPIO_Init(GPIOD, &GPIO_InitStruct);

  /**/
  GPIO_InitStruct.Pin = COL31_Pin|COL17_Pin|COL16_Pin|COL15_Pin
                          |COL14_Pin|COL13_Pin|COL12_Pin|COL11_Pin
                          |COL10_Pin;
  GPIO_InitStruct.Mode = LL_GPIO_MODE_INPUT;
  GPIO_InitStruct.Pull = LL_GPIO_PULL_NO;
  LL_GPIO_Init(GPIOD, &GPIO_InitStruct);

  /**/
  LL_EXTI_SetEXTISource(LL_EXTI_EXTI_PORTE, LL_EXTI_EXTI_LINE5);

  /**/
  EXTI_InitStruct.Line_0_31 = LL_EXTI_LINE_5;
  EXTI_InitStruct.LineCommand = ENABLE;
  EXTI_InitStruct.Mode = LL_EXTI_MODE_IT;
  EXTI_InitStruct.Trigger = LL_EXTI_TRIGGER_FALLING;
  LL_EXTI_Init(&EXTI_InitStruct);

  /**/
  LL_GPIO_SetPinPull(ENCODER_SW_GPIO_Port, ENCODER_SW_Pin, LL_GPIO_PULL_UP);

  /**/
  LL_GPIO_SetPinMode(ENCODER_SW_GPIO_Port, ENCODER_SW_Pin, LL_GPIO_MODE_INPUT);

  /* EXTI interrupt init*/
  NVIC_SetPriority(EXTI5_IRQn, NVIC_EncodePriority(NVIC_GetPriorityGrouping(),3, 0));
  NVIC_EnableIRQ(EXTI5_IRQn);

}

void Error_Handler(void)
{
  __disable_irq();
  while (1)
  {
  }
}
